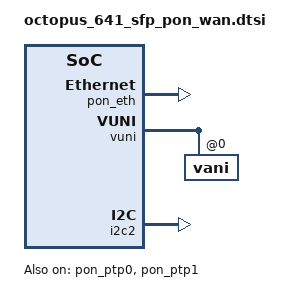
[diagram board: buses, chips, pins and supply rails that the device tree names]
// SPDX-License-Identifier: GPL-2.0
/*
 * Copyright (C) 2021-2022 MaxLinear, Inc.
 */

/ {
	wan: wan {
		ifname = "VANI0";
	};
};

&pon_eth {
	status = "okay";
	intel,altname = "sfp0";
};

&pon_ptp0 {
	status = "okay";
};

&pon_ptp1 {
	status = "okay";
};

&ponmbox {
	status = "okay";
	/* Reference to SFP cage for WAN */
	sfp = <&sfp_wan0>;
};

&vuni {
	status = "okay";
	vani@0 {
		mxl,extra-subif = "VANI0", "VUNI0_0", "VUNI0_1", "VUNI0_2";
		mxl,extra-subif-type = <SUBIF_VANI0_0 SUBIF_VUNI0_0 SUBIF_VUNI0_1 SUBIF_VUNI0_2>;
		mxl,extra-subif-domain = <VUNI_BR_DOMAIN_NO VUNI_BR_DOMAIN_UC VUNI_BR_DOMAIN_MC VUNI_BR_DOMAIN_BC>;
		mxl,num_ip_host = <2>;
	};
};

&i2c2 {
	status = "okay";
};

